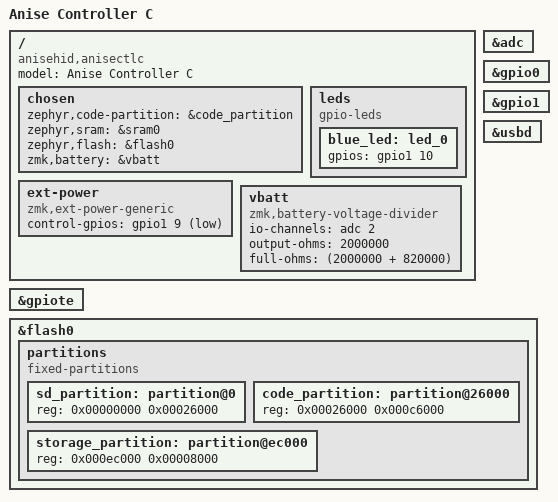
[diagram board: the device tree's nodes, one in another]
/*
 * Copyright (c) 2020 The ZMK Contributors
 *
 * SPDX-License-Identifier: MIT
 */

/dts-v1/;
#include <nordic/nrf52840_qiaa.dtsi>
#include <common/nordic/nrf52840_uf2_boot_mode.dtsi>
#include "anisectl_pins.dtsi"

/ {
    model = "Anise Controller C";
    compatible = "anisehid,anisectlc";

    chosen {
        zephyr,code-partition = &code_partition;
        zephyr,sram = &sram0;
        zephyr,flash = &flash0;
        zmk,battery = &vbatt;
    };

    leds {
        compatible = "gpio-leds";
        blue_led: led_0 {
            gpios = <&gpio1 10 GPIO_ACTIVE_HIGH>;
        };
    };

    ext-power {
        compatible = "zmk,ext-power-generic";
        control-gpios = <&gpio1 9 GPIO_ACTIVE_LOW>;
    };

    vbatt: vbatt {
        compatible = "zmk,battery-voltage-divider";
        io-channels = <&adc 2>;
        output-ohms = <2000000>;
        full-ohms = <(2000000 + 820000)>;
    };
};

&adc {
    status = "okay";
};

&gpiote {
    status = "okay";
};

&gpio0 {
    status = "okay";
};

&gpio1 {
    status = "okay";
};

zephyr_udc0: &usbd {
    status = "okay";
};

&flash0 {
    /*
     * Matches the Adafruit nRF52 bootloader with SoftDevice S140 6.1.1 that
     * ships on these boards: application starts at 0x26000. Do not change
     * without reflashing the bootloader to match.
     */
    partitions {
        compatible = "fixed-partitions";
        #address-cells = <1>;
        #size-cells = <1>;

        sd_partition: partition@0 {
            reg = <0x00000000 0x00026000>;
        };
        code_partition: partition@26000 {
            reg = <0x00026000 0x000c6000>;
        };

        /*
         * The flash starting at 0x000ec000 and ending at
         * 0x000f3fff is reserved for use by the application.
         */

        /*
         * Storage partition will be used by FCB/LittleFS/NVS
         * if enabled.
         */
        storage_partition: partition@ec000 {
            reg = <0x000ec000 0x00008000>;
        };
    };
};
